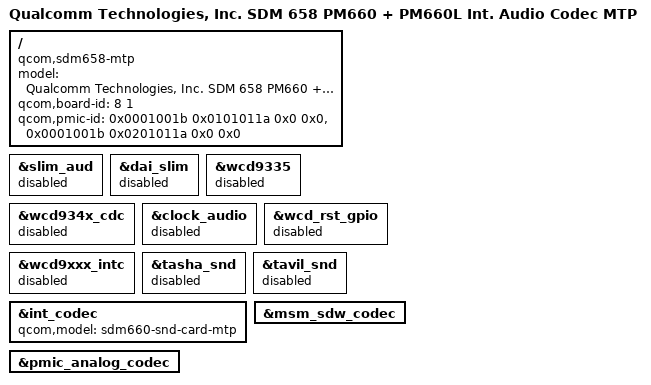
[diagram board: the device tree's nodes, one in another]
/* Copyright (c) 2016, The Linux Foundation. All rights reserved.
 *
 * This program is free software; you can redistribute it and/or modify
 * it under the terms of the GNU General Public License version 2 and
 * only version 2 as published by the Free Software Foundation.
 *
 * This program is distributed in the hope that it will be useful,
 * but WITHOUT ANY WARRANTY; without even the implied warranty of
 * MERCHANTABILITY or FITNESS FOR A PARTICULAR PURPOSE.  See the
 * GNU General Public License for more details.
 */


/dts-v1/;

#include "sdm658.dtsi"
#include "sdm660-mtp.dtsi"

/ {
	model = "Qualcomm Technologies, Inc. SDM 658 PM660 + PM660L Int. Audio Codec MTP";
	compatible = "qcom,sdm658-mtp", "qcom,sdm658", "qcom,mtp";
	qcom,board-id = <8 1>;
	qcom,pmic-id = <0x0001001b 0x0101011a 0x0 0x0>,
			<0x0001001b 0x0201011a 0x0 0x0>;
};

&slim_aud {
	status = "disabled";
};

&dai_slim {
	status = "disabled";
};

&wcd9335 {
	status = "disabled";
};

&wcd934x_cdc {
	status = "disabled";
};

&clock_audio {
	status = "disabled";
};

&wcd_rst_gpio {
	status = "disabled";
};

&wcd9xxx_intc {
	status = "disabled";
};

&tasha_snd {
	status = "disabled";
};

&tavil_snd {
	status = "disabled";
};

&int_codec {
	qcom,model = "sdm660-snd-card-mtp";
	status = "okay";
};

&pmic_analog_codec {
	status = "okay";
};

&msm_sdw_codec {
	status = "okay";
};
